# ATmega644 device description
Architecture: AVR8; Family: megaAVR
Registers are 8-bit, access not given, no defined reset value unless marked. A register's access mark holds for its fields unless they carry their own. Offsets are from the block's base; [hi:lo] are bit positions.

## TC2 (TC8_ASYNC module) — Timer/Counter, 8-bit Async
Instances: TC2 0x00
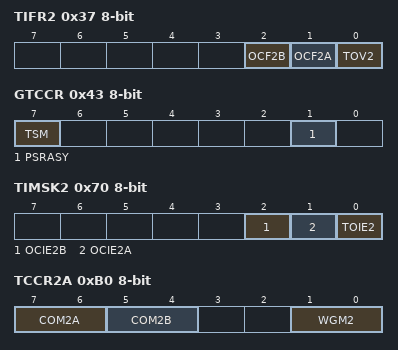
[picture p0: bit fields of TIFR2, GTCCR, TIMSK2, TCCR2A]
0x37 TIFR2 — Timer/Counter Interrupt Flag Register
  [2] OCF2B — Output Compare Flag 2B
  [1] OCF2A — Output Compare Flag 2A
  [0] TOV2 — Timer/Counter2 Overflow Flag
0x43 GTCCR — General Timer Counter Control register
  [7] TSM — Timer/Counter Synchronization Mode
  [1] PSRASY — Prescaler Reset Timer/Counter2
0x70 TIMSK2 — Timer/Counter Interrupt Mask register
  [2] OCIE2B — Timer/Counter2 Output Compare Match B Interrupt Enable
  [1] OCIE2A — Timer/Counter2 Output Compare Match A Interrupt Enable
  [0] TOIE2 — Timer/Counter2 Overflow Interrupt Enable
0xB0 TCCR2A — Timer/Counter2 Control Register A
  [7:6] COM2A — Compare Output Mode bits
  [5:4] COM2B — Compare Output Mode bits
  [1:0] WGM2 — Waveform Genration Mode
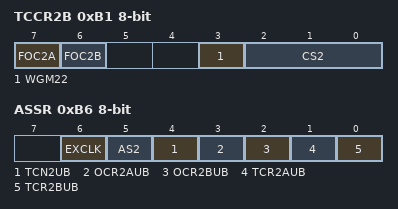
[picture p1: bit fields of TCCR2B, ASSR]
0xB1 TCCR2B — Timer/Counter2 Control Register B
  [7] FOC2A — Force Output Compare A
  [6] FOC2B — Force Output Compare B
  [3] WGM22 — Waveform Generation Mode
  [2:0] CS2 — Clock Select bits
    0=No Clock Source (Stopped); 1=Running, No Prescaling; 2=Running, CLK/8; 3=Running, CLK/32; 4=Running, CLK/64; 5=Running, CLK/128; 6=Running, CLK/256; 7=Running, CLK/1024
0xB2 TCNT2 — Timer/Counter2
0xB3 OCR2A — Timer/Counter2 Output Compare Register A
0xB4 OCR2B — Timer/Counter2 Output Compare Register B
0xB6 ASSR — Asynchronous Status Register
  [6] EXCLK — Enable External Clock Input
  [5] AS2 — Asynchronous Timer/Counter2
  [4] TCN2UB — Timer/Counter2 Update Busy
  [3] OCR2AUB — Output Compare Register2 Update Busy
  [2] OCR2BUB — Output Compare Register 2 Update Busy
  [1] TCR2AUB — Timer/Counter Control Register2 Update Busy
  [0] TCR2BUB — Timer/Counter Control Register2 Update Busy

## WDT — Watchdog Timer
Instances: WDT 0x00
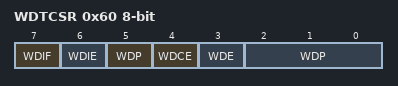
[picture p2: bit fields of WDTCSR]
0x60 WDTCSR — Watchdog Timer Control Register
  [7] WDIF — Watchdog Timeout Interrupt Flag
  [6] WDIE — Watchdog Timeout Interrupt Enable
  [4] WDCE — Watchdog Change Enable
  [3] WDE — Watch Dog Enable
  [5,2:0] WDP — Watchdog Timer Prescaler Bits
    0=Oscillator Cycles 2K; 1=Oscillator Cycles 4K; 2=Oscillator Cycles 8K; 3=Oscillator Cycles 16K; 4=Oscillator Cycles 32K; 5=Oscillator Cycles 64K; 6=Oscillator Cycles 128K; 7=Oscillator Cycles 256K; 8=Oscillator Cycles 512K; 9=Oscillator Cycles 1024K

## JTAG — JTAG Interface
Instances: JTAG 0x00
0x51 OCDR — On-Chip Debug Related Register in I/O Memory
0x54 MCUSR — MCU Status Register
  [4] JTRF — JTAG Reset Flag
0x55 MCUCR — MCU Control Register
  [7] JTD — JTAG Interface Disable

## BOOT_LOAD — Bootloader
Instances: BOOT_LOAD 0x00
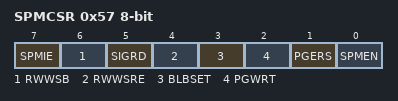
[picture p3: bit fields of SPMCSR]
0x57 SPMCSR — Store Program Memory Control Register
  [7] SPMIE — SPM Interrupt Enable
  [6] RWWSB — Read While Write Section Busy
  [5] SIGRD — Signature Row Read
  [4] RWWSRE — Read While Write section read enable
  [3] BLBSET — Boot Lock Bit Set
  [2] PGWRT — Page Write
  [1] PGERS — Page Erase
  [0] SPMEN — Store Program Memory Enable

## EXINT — External Interrupts
Instances: EXINT 0x00
0x3B PCIFR — Pin Change Interrupt Flag Register
  [3:0] PCIF — Pin Change Interrupt Flags
0x3C EIFR — External Interrupt Flag Register
  [2:0] INTF — External Interrupt Flags
0x3D EIMSK — External Interrupt Mask Register
  [2:0] INT — External Interrupt Request 2 Enable
0x68 PCICR — Pin Change Interrupt Control Register
  [3:0] PCIE — Pin Change Interrupt Enables
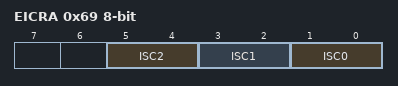
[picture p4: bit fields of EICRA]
0x69 EICRA — External Interrupt Control Register A
  [all] fields
    0=Low Level of INTX; 1=Any Logical Change of INTX; 2=Falling Edge of INTX; 3=Rising Edge of INTX
  [5:4] ISC2 — External Interrupt Sense Control Bit
  [3:2] ISC1 — External Interrupt Sense Control Bit
  [1:0] ISC0 — External Interrupt Sense Control Bit
0x6B PCMSK0 — Pin Change Mask Register 0
  [7:0] PCINT — Pin Change Enable Masks
0x6C PCMSK1 — Pin Change Mask Register 1
  [7:0] PCINT (bit 8 of the value upward) — Pin Change Enable Masks
0x6D PCMSK2 — Pin Change Mask Register 2
  [7:0] PCINT (bit 16 of the value upward) — Pin Change Enable Masks
0x73 PCMSK3 — Pin Change Mask Register 3
  [7:0] PCINT (bit 24 of the value upward) — Pin Change Enable Masks
